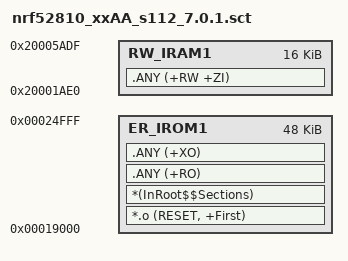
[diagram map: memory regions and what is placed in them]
; *************************************************************
; *** Scatter-Loading Description File generated by uVision ***
; *************************************************************

LR_IROM1 0x00019000 0x0000C000  {    ; load region size_region
  ER_IROM1 0x00019000 0x0000C000  {  ; load address = execution address
   *.o (RESET, +First)
   *(InRoot$$Sections)
   .ANY (+RO)
   .ANY (+XO)
  }
  RW_IRAM1 0x20001AE0 0x00004000  {  ; RW_data + ZI_data
   .ANY (+RW +ZI)
  }
}

